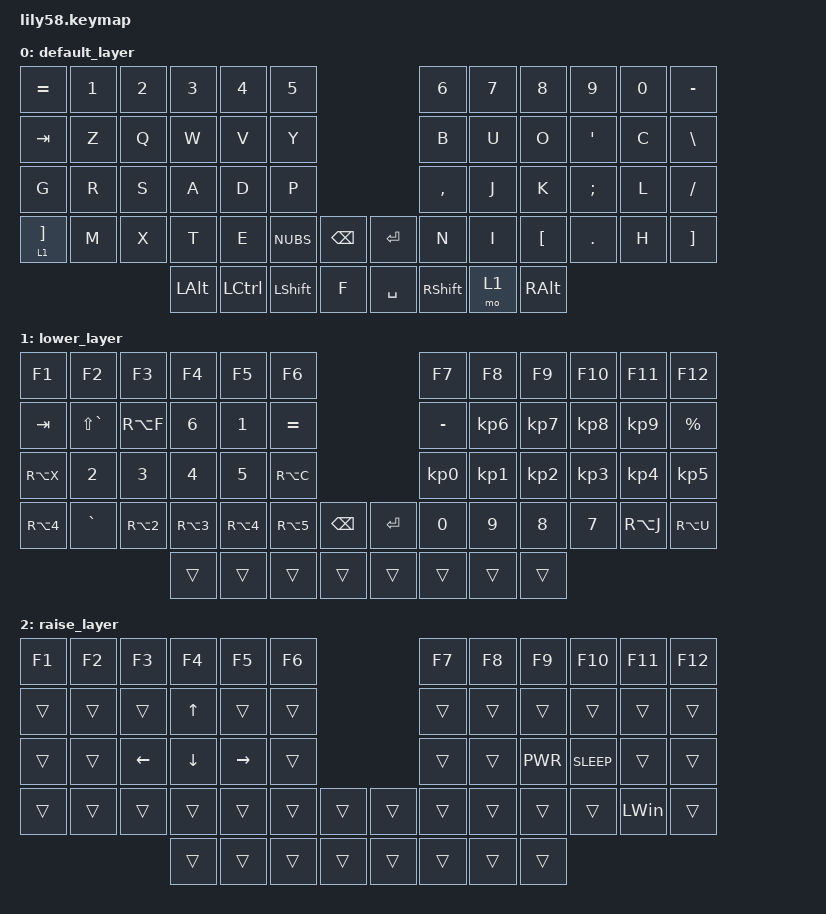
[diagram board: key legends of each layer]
/*
 * Copyright (c) 2020 The ZMK Contributors
 *
 * SPDX-License-Identifier: MIT
 */

#include <behaviors.dtsi>
#include <dt-bindings/zmk/keys.h>
#include <dt-bindings/zmk/bt.h>
#include <dt-bindings/zmk/ext_power.h>



#define COMBO(NAME, TIME, BINDINGS, KEYPOS) \
  combo_##NAME { \
    timeout-ms = <TIME>; \
    bindings = <BINDINGS>; \
    key-positions = <KEYPOS>; \
  };
//         _______________________               ________________________
//        |0  |1  |2  |3  |4  |5  |              |6  |7  |8  |9  |10 |11 |
//        |12 |13 |14 |15 |16 |17 |              |18 |19 |20 |21 |22 |23 |
//        |24 |25 |26 |27 |28 |29 |____      ____|30 |31 |32 |33 |34 |35 |
//        |36 |37 |38 |39 |40 |41 |42 |      |43 |44 |45 |46 |47 |48 |49 |
//        ‾‾‾‾‾‾‾‾|50 |51 |52 |53 |‾‾‾‾      ‾‾‾‾|54 |55 |56 |57 |‾‾‾‾‾‾‾‾           
//                 ‾‾‾‾‾‾‾‾‾‾‾‾‾‾‾                ‾‾‾‾‾‾‾‾‾‾‾‾‾‾‾‾
/ {
        combos {
                compatible = "zmk,combos";

                COMBO(circonflexe, 70, &kp Y, 20 21)
                COMBO(tiret, 70, &kp N8, 19 20)

                COMBO(fleche_haut, 50, &kp UP, 15 27)
                COMBO(fleche_bas, 50, &kp DOWN, 27 39)
                COMBO(fleche_gauche, 50, &kp LEFT, 24 25)              
                COMBO(fleche_droite, 50, &kp RIGHT, 28 29)

                COMBO(supr, 50, &kp DEL, 16 28)
                COMBO(retour, 50, &kp BSPC, 30 31)
                COMBO(retour_bis, 50, &kp BSPC, 17 29)
                COMBO(enter_un, 80, &kp ENTER, 25 26 27 28)
                COMBO(enter_two, 80, &kp ENTER, 26 27 28)
                COMBO(esc, 50, &kp ESC, 12 13)

                COMBO(ctrl_z, 50, &kp LC(LBKT), 37 38)
                COMBO(ctrl_c, 50, &kp LC(H), 38 39)
                COMBO(ctrl_v, 50, &kp LC(U), 39 40)
                COMBO(ctrl_s, 50, &kp LC(K), 16 17) 

//                COMBO(lower, 100, &mo 1, 40 42)

        };


	keymap {
		compatible = "zmk,keymap";

		default_layer {
		
			bindings = <
&kp EQUAL &kp N1 &kp N2 &kp N3  &kp N4   &kp N5                           &kp N6     &kp N7  &kp N8    &kp N9    &kp N0 &kp MINUS
&kp TAB	  &kp Z	 &kp Q	&kp W	&kp V    &kp Y                            &kp B	     &kp U	 &kp O	   &kp APOS	 &kp C	&kp BSLH
&kp G	  &kp R	 &kp S	&kp A	&kp D	 &kp P                            &kp COMMA  &kp J	 &kp K	   &kp SEMI	 &kp L	&kp SLASH
&lt 1 RBKT	  &kp M	 &kp X	&kp T	&kp E	 &kp NUBS   &kp BSPC	&kp ENTER &kp N	     &kp I	 &kp LBKT  &kp DOT   &kp H	&kp RBKT
                        &kp LALT&kp LCTRL &kp LSHFT	&kp F	    &kp SPACE &kp RSHFT	 &mo 1	 &kp RALT
			>;
		};

		lower_layer {
		
			bindings = <
&kp F1    &kp F2     &kp F3     &kp F4  &kp F5    &kp F6                          &kp F7    &kp F8     &kp F9      &kp F10    &kp F11    &kp F12
&kp TAB	  &kp LS(GRAVE)	 &kp RA(F)	&kp N6	&kp N1	  &kp EQUAL			              &kp MINUS	&kp KP_N6  &kp KP_N7   &kp KP_N8  &kp KP_N9	 &kp PRCNT
&kp RA(X)  &kp N2	 &kp N3	    &kp N4	&kp N5  &kp RA(C)			              &kp KP_N0	&kp KP_N1  &kp KP_N2   &kp KP_N3  &kp KP_N4	 &kp KP_N5
&kp RA(N4)  &kp GRAVE &kp RA(N2)	&kp RA(N3)	&kp RA(N4)	  &kp RA(N5)	&kp BSPC	&kp ENTER &kp N0	&kp N9	   &kp N8	   &kp N7	  &kp RA(J)  &kp RA(U)
                                &trans  &trans    &trans    &trans      &trans    &trans    &trans     &trans
			>;
		};

		raise_layer {

			bindings = <
&kp F1  &kp F2  &kp F3    &kp F4   &kp F5    &kp F6                       &kp F7  &kp F8  &kp F9    &kp F10    &kp F11   &kp F12
&trans  &trans  &trans    &kp UP   &trans    &trans                       &trans  &trans  &trans    &trans     &trans    &trans
&trans  &trans  &kp LEFT  &kp DOWN &kp RIGHT &trans                       &trans  &trans  &kp K_PWR	&kp K_SLEEP&trans    &trans
&trans  &trans  &trans    &trans   &trans    &trans    &trans   &trans    &trans  &trans  &trans    &trans     &kp LWIN  &trans
                          &trans   &trans    &trans    &trans   &trans    &trans  &trans  &trans
			>;


		};
	};
};
